# UPD70F3508 register map
Vendor: Renesas; Series: V850E2/Px4; File version: 1.0
CPU: other r0p0, little endian, no MPU, FPU, 4 interrupt priority bits
Registers are 8-bit, read-write, reset 0x0 unless marked. A register's access mark holds for its fields unless they carry their own. Offsets are from the block's base; [hi:lo] are bit positions; {n}, {i} and the like mark numbered series.

## DCRA1_CTL — Data CRC Function A, instance 1 — CTL register (base1 = 0xFF837000)
Base 0xFF837020
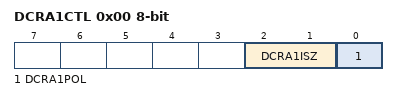
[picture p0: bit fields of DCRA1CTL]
0x00 DCRA1CTL — CRC Control Register — instance 1; selects polynomial and input bit width
  [2:1] DCRA1ISZ — CRC input bit width: 00=32-bit, 01=16-bit, 10=8-bit, 11=prohibited
  [0] DCRA1POL — CRC polynomial select: 0=32-bit Ethernet (04C11DB7H) LSB-first, 1=16-bit CCITT (1021H) MSB-first

## INTC_CFG — Interrupt Controller FE/EI Switch and Flag Registers
Base 0xFF83A000
0x00 INTCFGB — FE Level Interrupt Switch Register
  [7] INTCFGSL0 — FE-to-EI level switch (0=FE 1=EI for INTCME/ISG/WDTA0NMI/CLMA0-2)
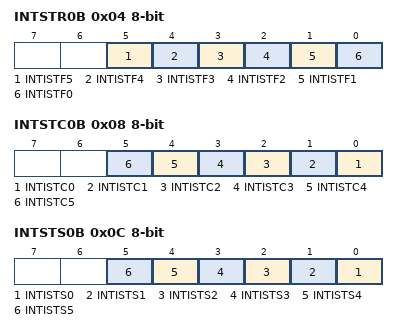
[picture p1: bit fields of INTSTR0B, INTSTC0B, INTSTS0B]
0x04 INTSTR0B ro — Interrupt Request Flag Storage Register
  [5] INTISTF5 — INTCLMA2 interrupt request flag
  [4] INTISTF4 — INTCLMA1 interrupt request flag
  [3] INTISTF3 — INTCLMA0 interrupt request flag
  [2] INTISTF2 — INTWDTA0NMI interrupt request flag
  [1] INTISTF1 — INTISG interrupt request flag
  [0] INTISTF0 — INTCME interrupt request flag
0x08 INTSTC0B wo — Interrupt Request Flag Clearing Register
  [n] INTISTC{n} (n=0..5) — Clear INTISTF{n} flag
0x0C INTSTS0B wo — Interrupt Request Flag Setting Register
  [n] INTISTS{n} (n=0..5) — Set INTISTF{n} flag

## BIST — Self-Diagnostic BIST Sequence and Protection Registers
Base 0xFF83B000
0x00 BSEQ0TCRPCMD 32-bit wo — BIST Protection Command Register — write-enable command for write-protected BIST registers
0x04 BSEQ0TCRPESR 32-bit ro — BIST Protection Status Register — protection error detection status
  [0] PESR0 — Protected-write-sequence error detected (0=no error, 1=error detected)
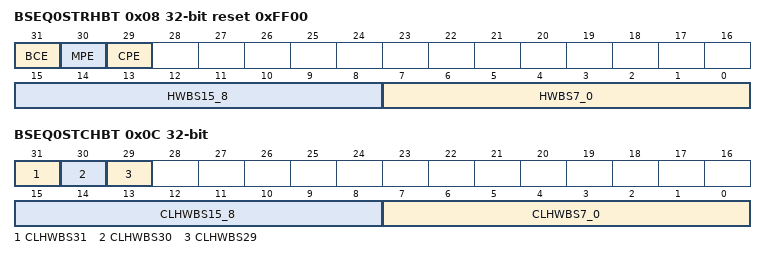
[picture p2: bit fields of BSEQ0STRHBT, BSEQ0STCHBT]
0x08 BSEQ0STRHBT 32-bit ro reset 0xFF00 — Self-Diagnostic BIST Status Register — BIST sequence error and completion flags
  [31] BCE — BIST sequencer comparison error (0=no error, 1=error)
  [30] MPE — Self-diagnostic BIST code-parity error on master side (0=no error, 1=error)
  [29] CPE — Self-diagnostic BIST code-parity error on checker side (0=no error, 1=error)
  [15:8] HWBS15_8 — Checker BIST sequencer state bits [15:8] (0=ended normally, 1=ended abnormally/not ended/not started)
  [7:0] HWBS7_0 — Master BIST sequencer state bits [7:0] (0=abnormal/not ended/not started, 1=ended normally)
0x0C BSEQ0STCHBT 32-bit wo — Self-Diagnostic BIST Status Clear Trigger Register — clears error flags in BSEQ0STRHBT (write-protected sequence required)
  [31] CLHWBS31 — Clear BSEQ0STRHBT.BCE (bit 31)
  [30] CLHWBS30 — Clear BSEQ0STRHBT.MPE (bit 30)
  [29] CLHWBS29 — Clear BSEQ0STRHBT.CPE (bit 29)
  [15:8] CLHWBS15_8 — Clear BSEQ0STRHBT.HWBS[15:8] checker state bits
  [7:0] CLHWBS7_0 — Clear BSEQ0STRHBT.HWBS[7:0] master state bits

## SGAM — Safety Guardian Master register area
Base 0xFF83C000
0x00 SGAMESET 32-bit wo — SGA master error set trigger register
  [0] SGAMEST — SGA error set trigger: 1=initiate active state of SGATERROUTZ (low)
0x04 SGAMECLR 32-bit wo — SGA master error clear trigger register
  [0] SGAMECT — SGA error clear trigger: 1=initiate inactive state of SGATERROUTZ (high)
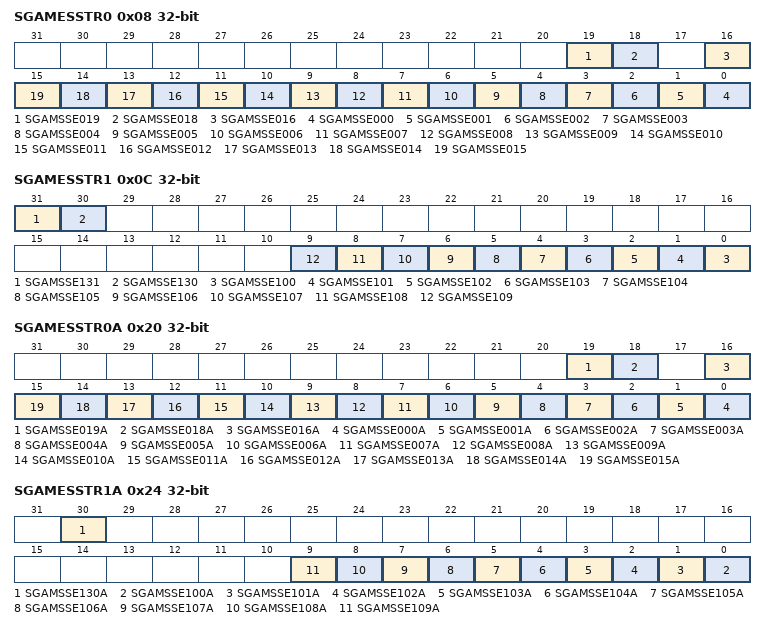
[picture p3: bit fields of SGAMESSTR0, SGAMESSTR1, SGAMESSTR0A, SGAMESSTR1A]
0x08 SGAMESSTR0 32-bit ro — SGA master error source status register 0
  [19] SGAMSSE019 — SGATERRIN19 error status
  [18] SGAMSSE018 — SGATERRIN18 error status
  [16] SGAMSSE016 — SGATERRIN16 error status (not present on UPD70F3508/3509)
  [n] SGAMSSE{n:03} (n=0..15) — SGATERRIN{n} error status
0x0C SGAMESSTR1 32-bit ro — SGA master error source status register 1
  [31] SGAMSSE131 — Error output loop-back state (SGATERRLB): 0=low, 1=high
  [30] SGAMSSE130 — SGAmESET write status (SGATERRSWS): 1=error set by SGAmEST
  [n-100] SGAMSSE{n} (n=100..109) — SGATERRIN{n-68} error status
0x10 SGAMPCMD0 32-bit wo — SGA master protection command register
  [7:0] SGAM0REG — Protection command [7:0] to enable writing to SGAM registers
0x20 SGAMESSTR0A 32-bit ro — SGA master error source status register 0A (majority A)
  [19] SGAMSSE019A — SGATERRIN19 majority-A status
  [18] SGAMSSE018A — SGATERRIN18 majority-A status
  [16] SGAMSSE016A — SGATERRIN16 majority-A status (not present on UPD70F3508/3509)
  [n] SGAMSSE{n:03}A (n=0..15) — SGATERRIN{n} majority-A status
0x24 SGAMESSTR1A 32-bit ro — SGA master error source status register 1A (majority A)
  [30] SGAMSSE130A — Error set trigger state majority-A (SGATERRSWS)
  [n-100] SGAMSSE{n}A (n=100..109) — SGATERRIN{n-68} majority-A status
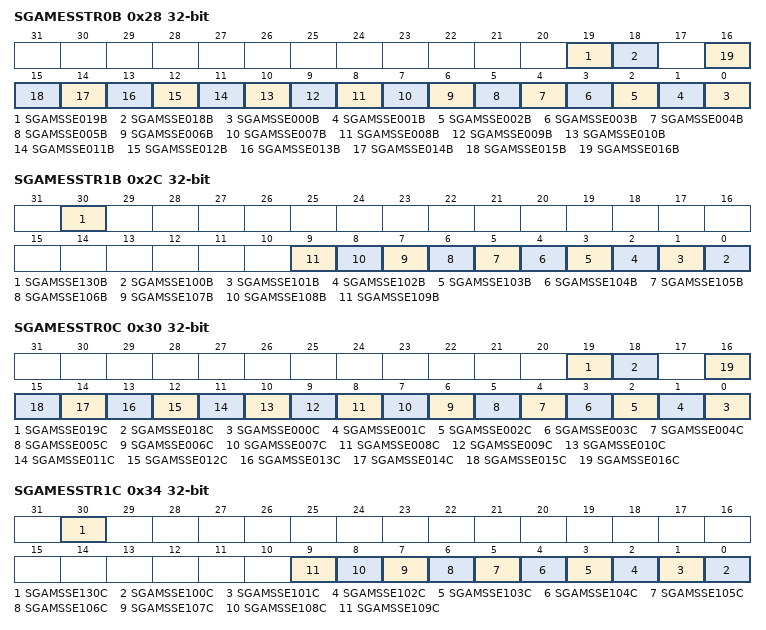
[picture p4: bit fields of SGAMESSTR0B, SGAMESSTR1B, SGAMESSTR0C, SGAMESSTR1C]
0x28 SGAMESSTR0B 32-bit ro — SGA master error source status register 0B (majority B)
  [19] SGAMSSE019B — SGATERRIN19 majority-B status
  [18] SGAMSSE018B — SGATERRIN18 majority-B status
  [n] SGAMSSE{n:03}B (n=0..16) — SGATERRIN{n} majority-B status
0x2C SGAMESSTR1B 32-bit ro — SGA master error source status register 1B (majority B)
  [30] SGAMSSE130B — Error set trigger state majority-B (SGATERRSWS)
  [n-100] SGAMSSE{n}B (n=100..109) — SGATERRIN{n-68} majority-B status
0x30 SGAMESSTR0C 32-bit ro — SGA master error source status register 0C (majority C)
  [19] SGAMSSE019C — SGATERRIN19 majority-C status
  [18] SGAMSSE018C — SGATERRIN18 majority-C status
  [n] SGAMSSE{n:03}C (n=0..16) — SGATERRIN{n} majority-C status
0x34 SGAMESSTR1C 32-bit ro — SGA master error source status register 1C (majority C)
  [30] SGAMSSE130C — Error set trigger state majority-C (SGATERRSWS)
  [n-100] SGAMSSE{n}C (n=100..109) — SGATERRIN{n-68} majority-C status
